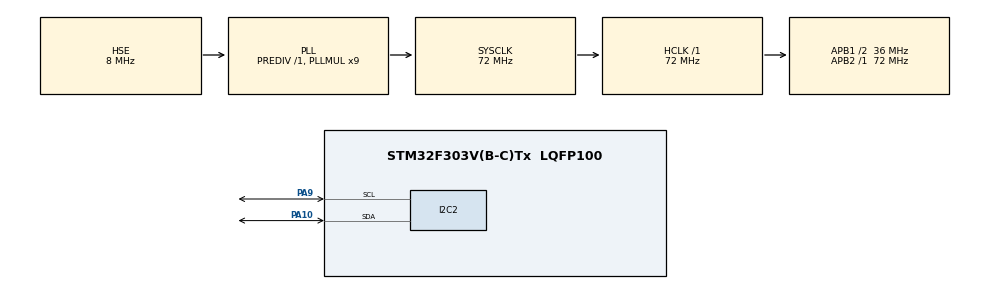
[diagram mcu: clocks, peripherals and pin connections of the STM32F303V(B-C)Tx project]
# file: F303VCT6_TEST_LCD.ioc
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Mcu.Family=STM32F3
Mcu.Name=STM32F303V(B-C)Tx
Mcu.Package=LQFP100
NVIC.PriorityGroup=NVIC_PRIORITYGROUP_4
PA10.Mode=I2C
PA10.Signal=I2C2_SDA
PA13.Mode=Serial_Wire
PA13.Signal=SYS_JTMS-SWDIO
PA14.Mode=Serial_Wire
PA14.Signal=SYS_JTCK-SWCLK
PA9.Mode=I2C
PA9.Signal=I2C2_SCL
PF0-OSC_IN.Mode=HSE-External-Oscillator
PF0-OSC_IN.Signal=RCC_OSC_IN
PF1-OSC_OUT.Mode=HSE-External-Oscillator
PF1-OSC_OUT.Signal=RCC_OSC_OUT
ProjectManager.HeapSize=0x200
ProjectManager.StackSize=0x400
ProjectManager.TargetToolchain=STM32CubeIDE
RCC.AHBFreq_Value=72000000
RCC.APB1CLKDivider=RCC_HCLK_DIV2
RCC.APB1Freq_Value=36000000
RCC.APB1TimFreq_Value=72000000
RCC.APB2Freq_Value=72000000
RCC.APB2TimFreq_Value=72000000
RCC.CortexFreq_Value=72000000
RCC.HCLKFreq_Value=72000000
RCC.HSE_VALUE=8000000
RCC.HSI_VALUE=8000000
RCC.LSE_VALUE=32768
RCC.PLLMUL=RCC_PLL_MUL9
RCC.PLLSourceVirtual=RCC_PLLSOURCE_HSE
RCC.SYSCLKFreq_VALUE=72000000
RCC.SYSCLKSourceVirtual=RCC_SYSCLKSOURCE_PLLCLK
RCC.USBFreq_Value=72000000
board=custom

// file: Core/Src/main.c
/* USER CODE BEGIN Header */
/**
  ******************************************************************************
  * @file           : main.c
  * @brief          : Main program body
  ******************************************************************************
  * @attention
  *
  * Copyright (c) 2023 STMicroelectronics.
  * All rights reserved.
  *
  * This software is licensed under terms that can be found in the LICENSE file
  * in the root directory of this software component.
  * If no LICENSE file comes with this software, it is provided AS-IS.
  *
  ******************************************************************************
  */
/* USER CODE END Header */
#include "main.h"
#include "i2c.h"
#include "gpio.h"

/* USER CODE BEGIN Includes */

#include "i2c-lcd.h"

/* USER CODE END Includes */

void SystemClock_Config(void);

/* USER CODE BEGIN 0 */

	/*
		int row = 0;
		int col = 0;
	*/

/* USER CODE END 0 */

int main(void)
{

  /* MCU Configuration--------------------------------------------------------*/

  /* Reset of all peripherals, Initializes the Flash interface and the Systick. */
  HAL_Init();

  /* Configure the system clock */
  SystemClock_Config();

  /* Initialize all configured peripherals */
  MX_GPIO_Init();
  MX_I2C2_Init();
  /* USER CODE BEGIN 2 */

	  lcd_init ();
	  lcd_send_string ("ITC-01 Vs ITC-02");
	  HAL_Delay(1000);
	  lcd_put_cur(2, 2);

  /* USER CODE END 2 */

  /* Infinite loop */
  while (1)
  {

    /* USER CODE BEGIN 3 */

	  /*

		  for (int i=0;i<128;i++)
		  {
			  lcd_put_cur(row, col);

			  lcd_send_data(i+48);

			  col++;

			  if (col > 15) {row++; col = 0;}
			  if (row > 1) row=0;

			  HAL_Delay(250);
		  }

	   */

  }

  /* USER CODE END 3 */
}

void SystemClock_Config(void)
{
  RCC_OscInitTypeDef RCC_OscInitStruct = {0};
  RCC_ClkInitTypeDef RCC_ClkInitStruct = {0};
  RCC_PeriphCLKInitTypeDef PeriphClkInit = {0};

  /** Initializes the RCC Oscillators according to the specified parameters
  * in the RCC_OscInitTypeDef structure.
  */
  RCC_OscInitStruct.OscillatorType = RCC_OSCILLATORTYPE_HSI|RCC_OSCILLATORTYPE_HSE;
  RCC_OscInitStruct.HSEState = RCC_HSE_ON;
  RCC_OscInitStruct.HSEPredivValue = RCC_HSE_PREDIV_DIV1;
  RCC_OscInitStruct.HSIState = RCC_HSI_ON;
  RCC_OscInitStruct.HSICalibrationValue = RCC_HSICALIBRATION_DEFAULT;
  RCC_OscInitStruct.PLL.PLLState = RCC_PLL_ON;
  RCC_OscInitStruct.PLL.PLLSource = RCC_PLLSOURCE_HSE;
  RCC_OscInitStruct.PLL.PLLMUL = RCC_PLL_MUL9;
  if (HAL_RCC_OscConfig(&RCC_OscInitStruct) != HAL_OK)
  {
    Error_Handler();
  }

  /** Initializes the CPU, AHB and APB buses clocks
  */
  RCC_ClkInitStruct.ClockType = RCC_CLOCKTYPE_HCLK|RCC_CLOCKTYPE_SYSCLK
                              |RCC_CLOCKTYPE_PCLK1|RCC_CLOCKTYPE_PCLK2;
  RCC_ClkInitStruct.SYSCLKSource = RCC_SYSCLKSOURCE_PLLCLK;
  RCC_ClkInitStruct.AHBCLKDivider = RCC_SYSCLK_DIV1;
  RCC_ClkInitStruct.APB1CLKDivider = RCC_HCLK_DIV2;
  RCC_ClkInitStruct.APB2CLKDivider = RCC_HCLK_DIV1;

  if (HAL_RCC_ClockConfig(&RCC_ClkInitStruct, FLASH_LATENCY_2) != HAL_OK)
  {
    Error_Handler();
  }
  PeriphClkInit.PeriphClockSelection = RCC_PERIPHCLK_I2C2;
  PeriphClkInit.I2c2ClockSelection = RCC_I2C2CLKSOURCE_HSI;
  if (HAL_RCCEx_PeriphCLKConfig(&PeriphClkInit) != HAL_OK)
  {
    Error_Handler();
  }
}

void Error_Handler(void)
{
  __disable_irq();
  while (1)
  {
  }
}
